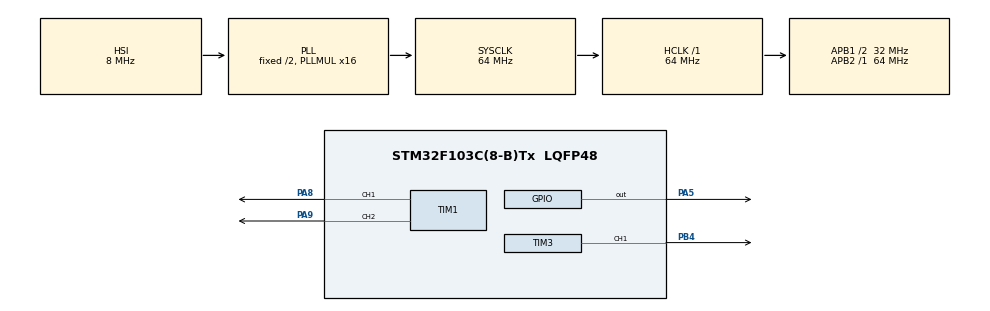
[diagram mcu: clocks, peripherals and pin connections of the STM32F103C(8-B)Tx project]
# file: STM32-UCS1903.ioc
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Dma.Request0=TIM1_CH2
Dma.Request1=TIM3_CH1/TRIG
Dma.Request2=TIM1_CH1
Dma.TIM1_CH1.2.Direction=DMA_MEMORY_TO_PERIPH
Dma.TIM1_CH1.2.Instance=DMA1_Channel2
Dma.TIM1_CH1.2.MemDataAlignment=DMA_MDATAALIGN_BYTE
Dma.TIM1_CH1.2.MemInc=DMA_MINC_ENABLE
Dma.TIM1_CH1.2.Mode=DMA_CIRCULAR
Dma.TIM1_CH1.2.PeriphDataAlignment=DMA_PDATAALIGN_WORD
Dma.TIM1_CH1.2.PeriphInc=DMA_PINC_DISABLE
Dma.TIM1_CH1.2.Priority=DMA_PRIORITY_MEDIUM
Dma.TIM1_CH2.0.Direction=DMA_MEMORY_TO_PERIPH
Dma.TIM1_CH2.0.Instance=DMA1_Channel3
Dma.TIM1_CH2.0.MemDataAlignment=DMA_MDATAALIGN_BYTE
Dma.TIM1_CH2.0.MemInc=DMA_MINC_ENABLE
Dma.TIM1_CH2.0.Mode=DMA_CIRCULAR
Dma.TIM1_CH2.0.PeriphDataAlignment=DMA_PDATAALIGN_WORD
Dma.TIM1_CH2.0.PeriphInc=DMA_PINC_DISABLE
Dma.TIM1_CH2.0.Priority=DMA_PRIORITY_LOW
Dma.TIM3_CH1/TRIG.1.Direction=DMA_MEMORY_TO_PERIPH
Dma.TIM3_CH1/TRIG.1.Instance=DMA1_Channel6
Dma.TIM3_CH1/TRIG.1.MemDataAlignment=DMA_MDATAALIGN_BYTE
Dma.TIM3_CH1/TRIG.1.MemInc=DMA_MINC_ENABLE
Dma.TIM3_CH1/TRIG.1.Mode=DMA_CIRCULAR
Dma.TIM3_CH1/TRIG.1.PeriphDataAlignment=DMA_PDATAALIGN_WORD
Dma.TIM3_CH1/TRIG.1.PeriphInc=DMA_PINC_DISABLE
Dma.TIM3_CH1/TRIG.1.Priority=DMA_PRIORITY_LOW
Mcu.Family=STM32F1
Mcu.Name=STM32F103C(8-B)Tx
Mcu.Package=LQFP48
NVIC.DMA1_Channel2_IRQn=true\:0\:0\:false\:false\:true\:false\:true\:true
NVIC.DMA1_Channel3_IRQn=true\:0\:0\:false\:false\:true\:false\:true\:true
NVIC.DMA1_Channel6_IRQn=true\:0\:0\:false\:false\:true\:false\:true\:true
NVIC.PriorityGroup=NVIC_PRIORITYGROUP_4
PA0-WKUP.Mode=SYS_WakeUp0
PA0-WKUP.Signal=SYS_WKUP
PA13.Mode=Serial_Wire
PA13.Signal=SYS_JTMS-SWDIO
PA14.Mode=Serial_Wire
PA14.Signal=SYS_JTCK-SWCLK
PA2.Signal=S_TIM2_CH3
PA3.Signal=S_TIM2_CH4
PA5.GPIO_Speed=GPIO_SPEED_FREQ_HIGH
PA5.Signal=GPIO_Output
PA8.GPIO_Speed=GPIO_SPEED_FREQ_HIGH
PA8.Signal=S_TIM1_CH1
PA9.GPIO_ModeDefaultPP=GPIO_MODE_AF_OD
PA9.GPIO_Speed=GPIO_SPEED_FREQ_HIGH
PA9.Signal=S_TIM1_CH2
PB13.GPIO_ModeDefaultPP=GPIO_MODE_AF_OD
PB13.GPIO_Speed=GPIO_SPEED_FREQ_HIGH
PB13.Signal=TIM1_CH1N
PB4.GPIO_ModeDefaultPP=GPIO_MODE_AF_OD
PB4.GPIO_Speed=GPIO_SPEED_FREQ_HIGH
PB4.Signal=S_TIM3_CH1
PB5.Signal=S_TIM3_CH2
PB6.GPIO_ModeDefaultPP=GPIO_MODE_AF_OD
PB6.GPIO_Speed=GPIO_SPEED_FREQ_HIGH
PB6.Signal=S_TIM4_CH1
ProjectManager.HeapSize=0x200
ProjectManager.StackSize=0x400
ProjectManager.TargetToolchain=STM32CubeIDE
RCC.AHBFreq_Value=64000000
RCC.APB1CLKDivider=RCC_HCLK_DIV2
RCC.APB1Freq_Value=32000000
RCC.APB1TimFreq_Value=64000000
RCC.APB2Freq_Value=64000000
RCC.APB2TimFreq_Value=64000000
RCC.HCLKFreq_Value=64000000
RCC.PLLMUL=RCC_PLL_MUL16
RCC.SYSCLKFreq_VALUE=64000000
RCC.SYSCLKSource=RCC_SYSCLKSOURCE_PLLCLK
RCC.USBFreq_Value=64000000
SH.S_TIM1_CH1.0=TIM1_CH1,PWM Generation1 CH1
SH.S_TIM1_CH2.0=TIM1_CH2,PWM Generation2 CH2
SH.S_TIM2_CH3.0=TIM2_CH3
SH.S_TIM2_CH4.0=TIM2_CH4
SH.S_TIM3_CH1.0=TIM3_CH1,PWM Generation1 CH1
SH.S_TIM3_CH2.0=TIM3_CH2
SH.S_TIM4_CH1.0=TIM4_CH1
TIM1.Channel-PWM\ Generation1\ CH1=TIM_CHANNEL_1
TIM1.Channel-PWM\ Generation2\ CH2=TIM_CHANNEL_2
TIM3.Channel-PWM\ Generation1\ CH1=TIM_CHANNEL_1
TIM3.OCMode_PWM-PWM\ Generation1\ CH1=TIM_OCMODE_PWM1
TIM3.TIM_MasterOutputTrigger=TIM_TRGO_OC1
TIM3.TIM_MasterSlaveMode=TIM_MASTERSLAVEMODE_DISABLE
VP_TIM1_VS_ClockSourceINT.Mode=Internal
VP_TIM3_VS_ClockSourceINT.Mode=Internal
board=custom

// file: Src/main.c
/* USER CODE BEGIN Header */
/**
  ******************************************************************************
  * @file           : main.c
  * @brief          : Main program body
  ******************************************************************************
  * @attention
  *
  * Copyright (c) 2024 STMicroelectronics.
  * All rights reserved.
  *
  * This software is licensed under terms that can be found in the LICENSE file
  * in the root directory of this software component.
  * If no LICENSE file comes with this software, it is provided AS-IS.
  *
  ******************************************************************************
  */
/* USER CODE END Header */
#include "main.h"

/* USER CODE BEGIN Includes */
#include "ARGB.h"
/* USER CODE END Includes */

TIM_HandleTypeDef htim1;
TIM_HandleTypeDef htim3;
DMA_HandleTypeDef hdma_tim1_ch2;
DMA_HandleTypeDef hdma_tim1_ch1;
DMA_HandleTypeDef hdma_tim3_ch1_trig;

void SystemClock_Config(void);
static void MX_GPIO_Init(void);
static void MX_DMA_Init(void);
static void MX_TIM1_Init(void);
static void MX_TIM3_Init(void);

int main(void)
{

  /* MCU Configuration--------------------------------------------------------*/

  /* Reset of all peripherals, Initializes the Flash interface and the Systick. */
  HAL_Init();

  /* Configure the system clock */
  SystemClock_Config();

  /* Initialize all configured peripherals */
  MX_GPIO_Init();
  MX_DMA_Init();
  MX_TIM1_Init();
  MX_TIM3_Init();
  /* USER CODE BEGIN 2 */
  ARGB_Init();
  ARGB_Clear();
  ARGB_SetRGB(0, 255, 0, 0);
 	 ARGB_SetRGB(1, 0, 255, 0);
 	 ARGB_SetRGB(2, 0, 0, 255);
 	 ARGB_SetRGB(3, 255, 0, 255);
 	 ARGB_SetRGB(4, 255, 255, 0);
 	 ARGB_SetRGB(5, 0, 255, 255);
 	while (ARGB_Ready() != ARGB_READY) ;
 	ARGB_Show();
 	//HAL_Delay(24);

  /* USER CODE END 2 */

  /* Infinite loop */

    /* USER CODE BEGIN 3 */

//	 HAL_Delay(100);

  /* USER CODE END 3 */
}

void SystemClock_Config(void)
{
  RCC_OscInitTypeDef RCC_OscInitStruct = {0};
  RCC_ClkInitTypeDef RCC_ClkInitStruct = {0};

  /** Initializes the RCC Oscillators according to the specified parameters
  * in the RCC_OscInitTypeDef structure.
  */
  RCC_OscInitStruct.OscillatorType = RCC_OSCILLATORTYPE_HSI;
  RCC_OscInitStruct.HSIState = RCC_HSI_ON;
  RCC_OscInitStruct.HSICalibrationValue = RCC_HSICALIBRATION_DEFAULT;
  RCC_OscInitStruct.PLL.PLLState = RCC_PLL_ON;
  RCC_OscInitStruct.PLL.PLLSource = RCC_PLLSOURCE_HSI_DIV2;
  RCC_OscInitStruct.PLL.PLLMUL = RCC_PLL_MUL16;
  if (HAL_RCC_OscConfig(&RCC_OscInitStruct) != HAL_OK)
  {
    Error_Handler();
  }

  /** Initializes the CPU, AHB and APB buses clocks
  */
  RCC_ClkInitStruct.ClockType = RCC_CLOCKTYPE_HCLK|RCC_CLOCKTYPE_SYSCLK
                              |RCC_CLOCKTYPE_PCLK1|RCC_CLOCKTYPE_PCLK2;
  RCC_ClkInitStruct.SYSCLKSource = RCC_SYSCLKSOURCE_PLLCLK;
  RCC_ClkInitStruct.AHBCLKDivider = RCC_SYSCLK_DIV1;
  RCC_ClkInitStruct.APB1CLKDivider = RCC_HCLK_DIV2;
  RCC_ClkInitStruct.APB2CLKDivider = RCC_HCLK_DIV1;

  if (HAL_RCC_ClockConfig(&RCC_ClkInitStruct, FLASH_LATENCY_2) != HAL_OK)
  {
    Error_Handler();
  }
}

static void MX_TIM1_Init(void)
{

  TIM_ClockConfigTypeDef sClockSourceConfig = {0};
  TIM_MasterConfigTypeDef sMasterConfig = {0};
  TIM_OC_InitTypeDef sConfigOC = {0};
  TIM_BreakDeadTimeConfigTypeDef sBreakDeadTimeConfig = {0};

  htim1.Instance = TIM1;
  htim1.Init.Prescaler = 0;
  htim1.Init.CounterMode = TIM_COUNTERMODE_UP;
  htim1.Init.Period = 65535;
  htim1.Init.ClockDivision = TIM_CLOCKDIVISION_DIV1;
  htim1.Init.RepetitionCounter = 0;
  htim1.Init.AutoReloadPreload = TIM_AUTORELOAD_PRELOAD_DISABLE;
  if (HAL_TIM_Base_Init(&htim1) != HAL_OK)
  {
    Error_Handler();
  }
  sClockSourceConfig.ClockSource = TIM_CLOCKSOURCE_INTERNAL;
  if (HAL_TIM_ConfigClockSource(&htim1, &sClockSourceConfig) != HAL_OK)
  {
    Error_Handler();
  }
  if (HAL_TIM_PWM_Init(&htim1) != HAL_OK)
  {
    Error_Handler();
  }
  sMasterConfig.MasterOutputTrigger = TIM_TRGO_RESET;
  sMasterConfig.MasterSlaveMode = TIM_MASTERSLAVEMODE_DISABLE;
  if (HAL_TIMEx_MasterConfigSynchronization(&htim1, &sMasterConfig) != HAL_OK)
  {
    Error_Handler();
  }
  sConfigOC.OCMode = TIM_OCMODE_PWM1;
  sConfigOC.Pulse = 0;
  sConfigOC.OCPolarity = TIM_OCPOLARITY_HIGH;
  sConfigOC.OCNPolarity = TIM_OCNPOLARITY_HIGH;
  sConfigOC.OCFastMode = TIM_OCFAST_DISABLE;
  sConfigOC.OCIdleState = TIM_OCIDLESTATE_RESET;
  sConfigOC.OCNIdleState = TIM_OCNIDLESTATE_RESET;
  if (HAL_TIM_PWM_ConfigChannel(&htim1, &sConfigOC, TIM_CHANNEL_1) != HAL_OK)
  {
    Error_Handler();
  }
  if (HAL_TIM_PWM_ConfigChannel(&htim1, &sConfigOC, TIM_CHANNEL_2) != HAL_OK)
  {
    Error_Handler();
  }
  sBreakDeadTimeConfig.OffStateRunMode = TIM_OSSR_DISABLE;
  sBreakDeadTimeConfig.OffStateIDLEMode = TIM_OSSI_DISABLE;
  sBreakDeadTimeConfig.LockLevel = TIM_LOCKLEVEL_OFF;
  sBreakDeadTimeConfig.DeadTime = 0;
  sBreakDeadTimeConfig.BreakState = TIM_BREAK_DISABLE;
  sBreakDeadTimeConfig.BreakPolarity = TIM_BREAKPOLARITY_HIGH;
  sBreakDeadTimeConfig.AutomaticOutput = TIM_AUTOMATICOUTPUT_DISABLE;
  if (HAL_TIMEx_ConfigBreakDeadTime(&htim1, &sBreakDeadTimeConfig) != HAL_OK)
  {
    Error_Handler();
  }
  HAL_TIM_MspPostInit(&htim1);

}

static void MX_TIM3_Init(void)
{

  TIM_ClockConfigTypeDef sClockSourceConfig = {0};
  TIM_MasterConfigTypeDef sMasterConfig = {0};
  TIM_OC_InitTypeDef sConfigOC = {0};

  htim3.Instance = TIM3;
  htim3.Init.Prescaler = 0;
  htim3.Init.CounterMode = TIM_COUNTERMODE_UP;
  htim3.Init.Period = 65535;
  htim3.Init.ClockDivision = TIM_CLOCKDIVISION_DIV1;
  htim3.Init.AutoReloadPreload = TIM_AUTORELOAD_PRELOAD_DISABLE;
  if (HAL_TIM_Base_Init(&htim3) != HAL_OK)
  {
    Error_Handler();
  }
  sClockSourceConfig.ClockSource = TIM_CLOCKSOURCE_INTERNAL;
  if (HAL_TIM_ConfigClockSource(&htim3, &sClockSourceConfig) != HAL_OK)
  {
    Error_Handler();
  }
  if (HAL_TIM_PWM_Init(&htim3) != HAL_OK)
  {
    Error_Handler();
  }
  sMasterConfig.MasterOutputTrigger = TIM_TRGO_OC1;
  sMasterConfig.MasterSlaveMode = TIM_MASTERSLAVEMODE_DISABLE;
  if (HAL_TIMEx_MasterConfigSynchronization(&htim3, &sMasterConfig) != HAL_OK)
  {
    Error_Handler();
  }
  sConfigOC.OCMode = TIM_OCMODE_PWM1;
  sConfigOC.Pulse = 0;
  sConfigOC.OCPolarity = TIM_OCPOLARITY_HIGH;
  sConfigOC.OCFastMode = TIM_OCFAST_DISABLE;
  if (HAL_TIM_PWM_ConfigChannel(&htim3, &sConfigOC, TIM_CHANNEL_1) != HAL_OK)
  {
    Error_Handler();
  }
  HAL_TIM_MspPostInit(&htim3);

}

static void MX_DMA_Init(void)
{

  /* DMA controller clock enable */
  __HAL_RCC_DMA1_CLK_ENABLE();

  /* DMA interrupt init */
  /* DMA1_Channel2_IRQn interrupt configuration */
  HAL_NVIC_SetPriority(DMA1_Channel2_IRQn, 0, 0);
  HAL_NVIC_EnableIRQ(DMA1_Channel2_IRQn);
  /* DMA1_Channel3_IRQn interrupt configuration */
  HAL_NVIC_SetPriority(DMA1_Channel3_IRQn, 0, 0);
  HAL_NVIC_EnableIRQ(DMA1_Channel3_IRQn);
  /* DMA1_Channel6_IRQn interrupt configuration */
  HAL_NVIC_SetPriority(DMA1_Channel6_IRQn, 0, 0);
  HAL_NVIC_EnableIRQ(DMA1_Channel6_IRQn);

}

static void MX_GPIO_Init(void)
{
  GPIO_InitTypeDef GPIO_InitStruct = {0};

  /* GPIO Ports Clock Enable */
  __HAL_RCC_GPIOA_CLK_ENABLE();
  __HAL_RCC_GPIOB_CLK_ENABLE();

  /*Configure GPIO pin Output Level */
  HAL_GPIO_WritePin(GPIOA, GPIO_PIN_5, GPIO_PIN_RESET);

  /*Configure GPIO pins : PA2 PA3 */
  GPIO_InitStruct.Pin = GPIO_PIN_2|GPIO_PIN_3;
  GPIO_InitStruct.Mode = GPIO_MODE_AF_PP;
  GPIO_InitStruct.Speed = GPIO_SPEED_FREQ_LOW;
  HAL_GPIO_Init(GPIOA, &GPIO_InitStruct);

  /*Configure GPIO pin : PA5 */
  GPIO_InitStruct.Pin = GPIO_PIN_5;
  GPIO_InitStruct.Mode = GPIO_MODE_OUTPUT_PP;
  GPIO_InitStruct.Pull = GPIO_NOPULL;
  GPIO_InitStruct.Speed = GPIO_SPEED_FREQ_HIGH;
  HAL_GPIO_Init(GPIOA, &GPIO_InitStruct);

  /*Configure GPIO pin : PB6 */
  GPIO_InitStruct.Pin = GPIO_PIN_6;
  GPIO_InitStruct.Mode = GPIO_MODE_AF_OD;
  GPIO_InitStruct.Speed = GPIO_SPEED_FREQ_HIGH;
  HAL_GPIO_Init(GPIOB, &GPIO_InitStruct);

}

void Error_Handler(void)
{
  __disable_irq();
  while (1)
  {
  }
}
